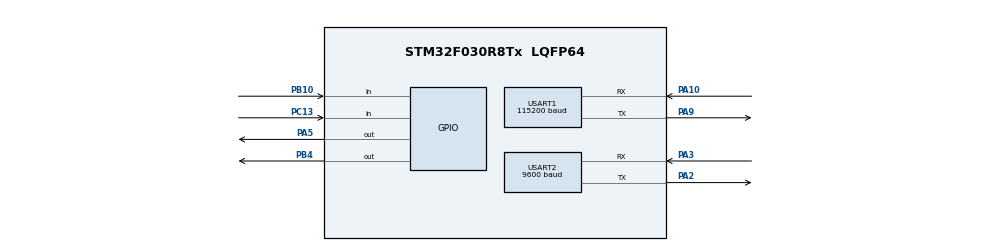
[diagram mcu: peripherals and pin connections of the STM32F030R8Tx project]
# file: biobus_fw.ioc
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Dma.Request0=USART2_RX
Dma.Request1=USART2_TX
Dma.Request2=USART1_RX
Dma.Request3=USART1_TX
Dma.USART1_RX.2.Direction=DMA_PERIPH_TO_MEMORY
Dma.USART1_RX.2.Instance=DMA1_Channel3
Dma.USART1_RX.2.MemDataAlignment=DMA_MDATAALIGN_BYTE
Dma.USART1_RX.2.MemInc=DMA_MINC_ENABLE
Dma.USART1_RX.2.Mode=DMA_NORMAL
Dma.USART1_RX.2.PeriphDataAlignment=DMA_PDATAALIGN_BYTE
Dma.USART1_RX.2.PeriphInc=DMA_PINC_DISABLE
Dma.USART1_RX.2.Priority=DMA_PRIORITY_LOW
Dma.USART1_TX.3.Direction=DMA_MEMORY_TO_PERIPH
Dma.USART1_TX.3.Instance=DMA1_Channel2
Dma.USART1_TX.3.MemDataAlignment=DMA_MDATAALIGN_BYTE
Dma.USART1_TX.3.MemInc=DMA_MINC_ENABLE
Dma.USART1_TX.3.Mode=DMA_NORMAL
Dma.USART1_TX.3.PeriphDataAlignment=DMA_PDATAALIGN_BYTE
Dma.USART1_TX.3.PeriphInc=DMA_PINC_DISABLE
Dma.USART1_TX.3.Priority=DMA_PRIORITY_LOW
Dma.USART2_RX.0.Direction=DMA_PERIPH_TO_MEMORY
Dma.USART2_RX.0.Instance=DMA1_Channel5
Dma.USART2_RX.0.MemDataAlignment=DMA_MDATAALIGN_BYTE
Dma.USART2_RX.0.MemInc=DMA_MINC_ENABLE
Dma.USART2_RX.0.Mode=DMA_NORMAL
Dma.USART2_RX.0.PeriphDataAlignment=DMA_PDATAALIGN_BYTE
Dma.USART2_RX.0.PeriphInc=DMA_PINC_DISABLE
Dma.USART2_RX.0.Priority=DMA_PRIORITY_HIGH
Dma.USART2_TX.1.Direction=DMA_MEMORY_TO_PERIPH
Dma.USART2_TX.1.Instance=DMA1_Channel4
Dma.USART2_TX.1.MemDataAlignment=DMA_MDATAALIGN_BYTE
Dma.USART2_TX.1.MemInc=DMA_MINC_ENABLE
Dma.USART2_TX.1.Mode=DMA_NORMAL
Dma.USART2_TX.1.PeriphDataAlignment=DMA_PDATAALIGN_BYTE
Dma.USART2_TX.1.PeriphInc=DMA_PINC_DISABLE
Dma.USART2_TX.1.Priority=DMA_PRIORITY_LOW
FREERTOS.Tasks01=defaultTask,0,128,StartDefaultTask,Default,NULL
Mcu.Family=STM32F0
Mcu.Name=STM32F030R8Tx
Mcu.Package=LQFP64
NVIC.DMA1_Channel2_3_IRQn=true\:3\:0\:false\:false\:true\:true\:false\:true
NVIC.DMA1_Channel4_5_IRQn=true\:3\:0\:true\:false\:true\:true\:false\:true
NVIC.TIM3_IRQn=true\:3\:0\:false\:false\:true\:true\:true\:true
NVIC.USART1_IRQn=true\:3\:0\:false\:false\:true\:true\:true\:true
NVIC.USART2_IRQn=true\:3\:0\:false\:false\:true\:true\:true\:true
PA10.Mode=Asynchronous
PA10.Signal=USART1_RX
PA2.Mode=Asynchronous
PA2.Signal=USART2_TX
PA3.Mode=Asynchronous
PA3.Signal=USART2_RX
PA5.Signal=GPIO_Output
PA9.Mode=Asynchronous
PA9.Signal=USART1_TX
PB10.GPIO_Mode=GPIO_MODE_INPUT
PB10.GPIO_PuPd=GPIO_NOPULL
PB10.Signal=GPIO_Input
PB4.GPIO_ModeDefaultOutputPP=GPIO_MODE_OUTPUT_OD
PB4.GPIO_PuPd=GPIO_PULLUP
PB4.Signal=GPIO_Output
PC13.Signal=GPIO_Input
ProjectManager.HeapSize=0x200
ProjectManager.StackSize=0x400
ProjectManager.TargetToolchain=MDK-ARM V4
RCC.APB1Freq_Value=8000000
RCC.APB1TimFreq_Value=8000000
TIM3.Period=9
TIM3.Prescaler=799
TIM3.TIM_MasterOutputTrigger=TIM_TRGO_RESET
USART1.BaudRate=115200
USART1.StopBits=STOPBITS_2
USART1.VirtualMode-Asynchronous=VM_ASYNC
USART2.BaudRate=9600
USART2.StopBits=STOPBITS_2
USART2.VirtualMode-Asynchronous=VM_ASYNC
VP_FREERTOS_VS_CMSIS_V1.Mode=CMSIS_V1
VP_TIM3_VS_ClockSourceINT.Mode=Internal
board=custom

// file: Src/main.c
/* USER CODE BEGIN Header */
/**
  ******************************************************************************
  * @file           : main.c
  * @brief          : Main program body
  ******************************************************************************
  * @attention
  *
  * <h2><center>&copy; Copyright (c) 2019 STMicroelectronics.
  * All rights reserved.</center></h2>
  *
  * This software component is licensed by ST under Ultimate Liberty license
  * SLA0044, the "License"; You may not use this file except in compliance with
  * the License. You may obtain a copy of the License at:
  *                             www.st.com/SLA0044
  *
  ******************************************************************************
  */
/* USER CODE END Header */

#include "main.h"
#include "cmsis_os.h"

TIM_HandleTypeDef htim3;

UART_HandleTypeDef huart1;
UART_HandleTypeDef huart2;
DMA_HandleTypeDef hdma_usart1_rx;
DMA_HandleTypeDef hdma_usart1_tx;
DMA_HandleTypeDef hdma_usart2_rx;
DMA_HandleTypeDef hdma_usart2_tx;

osThreadId defaultTaskHandle;

void SystemClock_Config(void);
static void MX_GPIO_Init(void);
static void MX_DMA_Init(void);
static void MX_USART2_UART_Init(void);
static void MX_USART1_UART_Init(void);
static void MX_TIM3_Init(void);
void StartDefaultTask(void const * argument);

/* USER CODE BEGIN PFP */
extern void test(void) ;
/* USER CODE END PFP */

int main(void)
{

  /* MCU Configuration--------------------------------------------------------*/

  /* Reset of all peripherals, Initializes the Flash interface and the Systick. */
  HAL_Init();

  /* Configure the system clock */
  SystemClock_Config();

  /* Initialize all configured peripherals */
  MX_GPIO_Init();
  MX_DMA_Init();
  MX_USART2_UART_Init();
  MX_USART1_UART_Init();
  MX_TIM3_Init();

  /* Create the thread(s) */
  /* definition and creation of defaultTask */
  osThreadDef(defaultTask, StartDefaultTask, osPriorityNormal, 0, 128);
  defaultTaskHandle = osThreadCreate(osThread(defaultTask), NULL);

  /* Start scheduler */
  osKernelStart();

  /* We should never get here as control is now taken by the scheduler */

  /* Infinite loop */
  while (1)
  {

  }
}

void SystemClock_Config(void)
{
  RCC_OscInitTypeDef RCC_OscInitStruct = {0};
  RCC_ClkInitTypeDef RCC_ClkInitStruct = {0};
  RCC_PeriphCLKInitTypeDef PeriphClkInit = {0};

  /** Initializes the CPU, AHB and APB busses clocks
  */
  RCC_OscInitStruct.OscillatorType = RCC_OSCILLATORTYPE_HSI;
  RCC_OscInitStruct.HSIState = RCC_HSI_ON;
  RCC_OscInitStruct.HSICalibrationValue = RCC_HSICALIBRATION_DEFAULT;
  RCC_OscInitStruct.PLL.PLLState = RCC_PLL_NONE;
  if (HAL_RCC_OscConfig(&RCC_OscInitStruct) != HAL_OK)
  {
    Error_Handler();
  }
  /** Initializes the CPU, AHB and APB busses clocks
  */
  RCC_ClkInitStruct.ClockType = RCC_CLOCKTYPE_HCLK|RCC_CLOCKTYPE_SYSCLK
                              |RCC_CLOCKTYPE_PCLK1;
  RCC_ClkInitStruct.SYSCLKSource = RCC_SYSCLKSOURCE_HSI;
  RCC_ClkInitStruct.AHBCLKDivider = RCC_SYSCLK_DIV1;
  RCC_ClkInitStruct.APB1CLKDivider = RCC_HCLK_DIV1;

  if (HAL_RCC_ClockConfig(&RCC_ClkInitStruct, FLASH_LATENCY_0) != HAL_OK)
  {
    Error_Handler();
  }
  PeriphClkInit.PeriphClockSelection = RCC_PERIPHCLK_USART1;
  PeriphClkInit.Usart1ClockSelection = RCC_USART1CLKSOURCE_PCLK1;
  if (HAL_RCCEx_PeriphCLKConfig(&PeriphClkInit) != HAL_OK)
  {
    Error_Handler();
  }
}

static void MX_TIM3_Init(void)
{

  TIM_ClockConfigTypeDef sClockSourceConfig = {0};
  TIM_MasterConfigTypeDef sMasterConfig = {0};

  htim3.Instance = TIM3;
  htim3.Init.Prescaler = 799;
  htim3.Init.CounterMode = TIM_COUNTERMODE_UP;
  htim3.Init.Period = 9;
  htim3.Init.ClockDivision = TIM_CLOCKDIVISION_DIV1;
  htim3.Init.AutoReloadPreload = TIM_AUTORELOAD_PRELOAD_DISABLE;
  if (HAL_TIM_Base_Init(&htim3) != HAL_OK)
  {
    Error_Handler();
  }
  sClockSourceConfig.ClockSource = TIM_CLOCKSOURCE_INTERNAL;
  if (HAL_TIM_ConfigClockSource(&htim3, &sClockSourceConfig) != HAL_OK)
  {
    Error_Handler();
  }
  sMasterConfig.MasterOutputTrigger = TIM_TRGO_RESET;
  sMasterConfig.MasterSlaveMode = TIM_MASTERSLAVEMODE_DISABLE;
  if (HAL_TIMEx_MasterConfigSynchronization(&htim3, &sMasterConfig) != HAL_OK)
  {
    Error_Handler();
  }

}

static void MX_USART1_UART_Init(void)
{

  huart1.Instance = USART1;
  huart1.Init.BaudRate = 115200;
  huart1.Init.WordLength = UART_WORDLENGTH_8B;
  huart1.Init.StopBits = UART_STOPBITS_2;
  huart1.Init.Parity = UART_PARITY_NONE;
  huart1.Init.Mode = UART_MODE_TX_RX;
  huart1.Init.HwFlowCtl = UART_HWCONTROL_NONE;
  huart1.Init.OverSampling = UART_OVERSAMPLING_16;
  huart1.Init.OneBitSampling = UART_ONE_BIT_SAMPLE_DISABLE;
  huart1.AdvancedInit.AdvFeatureInit = UART_ADVFEATURE_NO_INIT;
  if (HAL_UART_Init(&huart1) != HAL_OK)
  {
    Error_Handler();
  }

}

static void MX_USART2_UART_Init(void)
{

  huart2.Instance = USART2;
  huart2.Init.BaudRate = 9600;
  huart2.Init.WordLength = UART_WORDLENGTH_8B;
  huart2.Init.StopBits = UART_STOPBITS_2;
  huart2.Init.Parity = UART_PARITY_NONE;
  huart2.Init.Mode = UART_MODE_TX_RX;
  huart2.Init.HwFlowCtl = UART_HWCONTROL_NONE;
  huart2.Init.OverSampling = UART_OVERSAMPLING_16;
  huart2.Init.OneBitSampling = UART_ONE_BIT_SAMPLE_DISABLE;
  huart2.AdvancedInit.AdvFeatureInit = UART_ADVFEATURE_NO_INIT;
  if (HAL_UART_Init(&huart2) != HAL_OK)
  {
    Error_Handler();
  }

}

static void MX_DMA_Init(void)
{

  /* DMA controller clock enable */
  __HAL_RCC_DMA1_CLK_ENABLE();

  /* DMA interrupt init */
  /* DMA1_Channel2_3_IRQn interrupt configuration */
  HAL_NVIC_SetPriority(DMA1_Channel2_3_IRQn, 3, 0);
  HAL_NVIC_EnableIRQ(DMA1_Channel2_3_IRQn);
  /* DMA1_Channel4_5_IRQn interrupt configuration */
  HAL_NVIC_SetPriority(DMA1_Channel4_5_IRQn, 3, 0);
  HAL_NVIC_EnableIRQ(DMA1_Channel4_5_IRQn);

}

static void MX_GPIO_Init(void)
{
  GPIO_InitTypeDef GPIO_InitStruct = {0};

  /* GPIO Ports Clock Enable */
  __HAL_RCC_GPIOC_CLK_ENABLE();
  __HAL_RCC_GPIOA_CLK_ENABLE();
  __HAL_RCC_GPIOB_CLK_ENABLE();

  /*Configure GPIO pin Output Level */
  HAL_GPIO_WritePin(GPIOA, GPIO_PIN_5, GPIO_PIN_RESET);

  /*Configure GPIO pin Output Level */
  HAL_GPIO_WritePin(GPIOB, GPIO_PIN_4, GPIO_PIN_RESET);

  /*Configure GPIO pin : PC13 */
  GPIO_InitStruct.Pin = GPIO_PIN_13;
  GPIO_InitStruct.Mode = GPIO_MODE_INPUT;
  GPIO_InitStruct.Pull = GPIO_NOPULL;
  HAL_GPIO_Init(GPIOC, &GPIO_InitStruct);

  /*Configure GPIO pin : PA5 */
  GPIO_InitStruct.Pin = GPIO_PIN_5;
  GPIO_InitStruct.Mode = GPIO_MODE_OUTPUT_PP;
  GPIO_InitStruct.Pull = GPIO_NOPULL;
  GPIO_InitStruct.Speed = GPIO_SPEED_FREQ_LOW;
  HAL_GPIO_Init(GPIOA, &GPIO_InitStruct);

  /*Configure GPIO pin : PB10 */
  GPIO_InitStruct.Pin = GPIO_PIN_10;
  GPIO_InitStruct.Mode = GPIO_MODE_INPUT;
  GPIO_InitStruct.Pull = GPIO_NOPULL;
  HAL_GPIO_Init(GPIOB, &GPIO_InitStruct);

  /*Configure GPIO pin : PB4 */
  GPIO_InitStruct.Pin = GPIO_PIN_4;
  GPIO_InitStruct.Mode = GPIO_MODE_OUTPUT_OD;
  GPIO_InitStruct.Pull = GPIO_PULLUP;
  GPIO_InitStruct.Speed = GPIO_SPEED_FREQ_LOW;
  HAL_GPIO_Init(GPIOB, &GPIO_InitStruct);

}

void StartDefaultTask(void const * argument)
{

  /* USER CODE BEGIN 5 */
  /* Infinite loop */
  for(;;)
  {
    test();
  }
  /* USER CODE END 5 */
}

void Error_Handler(void)
{
}

/************************ (C) COPYRIGHT STMicroelectronics *****END OF FILE****/
